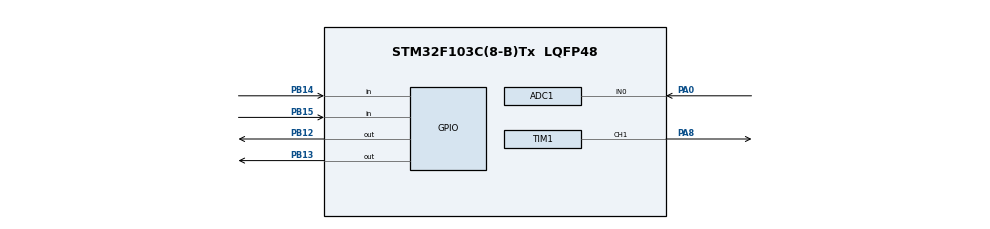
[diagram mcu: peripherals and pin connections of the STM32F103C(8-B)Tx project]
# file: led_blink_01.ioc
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ADC1.Channel-2\#ChannelRegularConversion=ADC_CHANNEL_0
ADC1.NbrOfConversionFlag=1
ADC1.Rank-2\#ChannelRegularConversion=1
ADC1.SamplingTime-2\#ChannelRegularConversion=ADC_SAMPLETIME_1CYCLE_5
ADC1.master=1
Mcu.Family=STM32F1
Mcu.Name=STM32F103C(8-B)Tx
Mcu.Package=LQFP48
NVIC.PriorityGroup=NVIC_PRIORITYGROUP_4
PA0-WKUP.Signal=ADCx_IN0
PA13.Mode=Serial_Wire
PA13.Signal=SYS_JTMS-SWDIO
PA14.Mode=Serial_Wire
PA14.Signal=SYS_JTCK-SWCLK
PA8.Signal=S_TIM1_CH1
PB12.Signal=GPIO_Output
PB13.Signal=GPIO_Output
PB14.Signal=GPIO_Input
PB15.Signal=GPIO_Input
ProjectManager.HeapSize=0x200
ProjectManager.StackSize=0x400
ProjectManager.TargetToolchain=Makefile
RCC.APB1Freq_Value=8000000
RCC.APB2Freq_Value=8000000
SH.ADCx_IN0.0=ADC1_IN0,IN0
SH.S_TIM1_CH1.0=TIM1_CH1,Output Compare1 CH1
TIM1.Channel-Output\ Compare1\ CH1=TIM_CHANNEL_1
board=custom

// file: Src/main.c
/* USER CODE BEGIN Header */
/**
  ******************************************************************************
  * @file           : main.c
  * @brief          : Main program body
  ******************************************************************************
  * @attention
  *
  * <h2><center>&copy; Copyright (c) 2019 STMicroelectronics.
  * All rights reserved.</center></h2>
  *
  * This software component is licensed by ST under BSD 3-Clause license,
  * the "License"; You may not use this file except in compliance with the
  * License. You may obtain a copy of the License at:
  *                        opensource.org/licenses/BSD-3-Clause
  *
  ******************************************************************************
  */
/* USER CODE END Header */

#include "main.h"
#include "adc.h"
#include "tim.h"
#include "gpio.h"

void SystemClock_Config(void);

/* USER CODE BEGIN 0 */

// STM32F103C8T6
#define C8_ONBOARD_LED_ON    HAL_GPIO_WritePin(GPIOB, GPIO_PIN_12, GPIO_PIN_SET);
#define C8_ONBOARD_LED_OFF   HAL_GPIO_WritePin(GPIOB, GPIO_PIN_12, GPIO_PIN_RESET);

void hello_led_blink()
{
    // HAL_GPIO_TogglePin(GPIOC, GPIO_PIN_13);
    // HAL_Delay(100);
    HAL_Delay(10);
    C8_ONBOARD_LED_ON
    HAL_Delay(400);
    for (int i = 0; i < 5; i++)
    {
        C8_ONBOARD_LED_OFF
        HAL_Delay(150);
        C8_ONBOARD_LED_ON
        HAL_Delay(250);
    }
    C8_ONBOARD_LED_ON
    HAL_Delay(1000);
}

int main(void)
{

    /* MCU Configuration--------------------------------------------------------*/

    /* Reset of all peripherals, Initializes the Flash interface and the Systick. */
    HAL_Init();

    /* Configure the system clock */
    SystemClock_Config();

    /* Initialize all configured peripherals */
    MX_GPIO_Init();
    MX_TIM1_Init();
    MX_ADC1_Init();

    /* USER CODE BEGIN 2 */
    hello_led_blink();
    /* USER CODE END 2 */

    /* Infinite loop */
    while (1)
    {
        C8_ONBOARD_LED_OFF
        HAL_Delay(80);
        C8_ONBOARD_LED_ON
        HAL_Delay(1500);
    }
}

void SystemClock_Config(void)
{
    RCC_OscInitTypeDef RCC_OscInitStruct = {0};
    RCC_ClkInitTypeDef RCC_ClkInitStruct = {0};
    RCC_PeriphCLKInitTypeDef PeriphClkInit = {0};

    /** Initializes the CPU, AHB and APB busses clocks
  */
    RCC_OscInitStruct.OscillatorType = RCC_OSCILLATORTYPE_HSI;
    RCC_OscInitStruct.HSIState = RCC_HSI_ON;
    RCC_OscInitStruct.HSICalibrationValue = RCC_HSICALIBRATION_DEFAULT;
    RCC_OscInitStruct.PLL.PLLState = RCC_PLL_NONE;
    if (HAL_RCC_OscConfig(&RCC_OscInitStruct) != HAL_OK)
    {
        Error_Handler();
    }
    /** Initializes the CPU, AHB and APB busses clocks
  */
    RCC_ClkInitStruct.ClockType = RCC_CLOCKTYPE_HCLK | RCC_CLOCKTYPE_SYSCLK | RCC_CLOCKTYPE_PCLK1 | RCC_CLOCKTYPE_PCLK2;
    RCC_ClkInitStruct.SYSCLKSource = RCC_SYSCLKSOURCE_HSI;
    RCC_ClkInitStruct.AHBCLKDivider = RCC_SYSCLK_DIV1;
    RCC_ClkInitStruct.APB1CLKDivider = RCC_HCLK_DIV1;
    RCC_ClkInitStruct.APB2CLKDivider = RCC_HCLK_DIV1;

    if (HAL_RCC_ClockConfig(&RCC_ClkInitStruct, FLASH_LATENCY_0) != HAL_OK)
    {
        Error_Handler();
    }
    PeriphClkInit.PeriphClockSelection = RCC_PERIPHCLK_ADC;
    PeriphClkInit.AdcClockSelection = RCC_ADCPCLK2_DIV2;
    if (HAL_RCCEx_PeriphCLKConfig(&PeriphClkInit) != HAL_OK)
    {
        Error_Handler();
    }
}

void Error_Handler(void)
{
}

/************************ (C) COPYRIGHT STMicroelectronics *****END OF FILE****/
